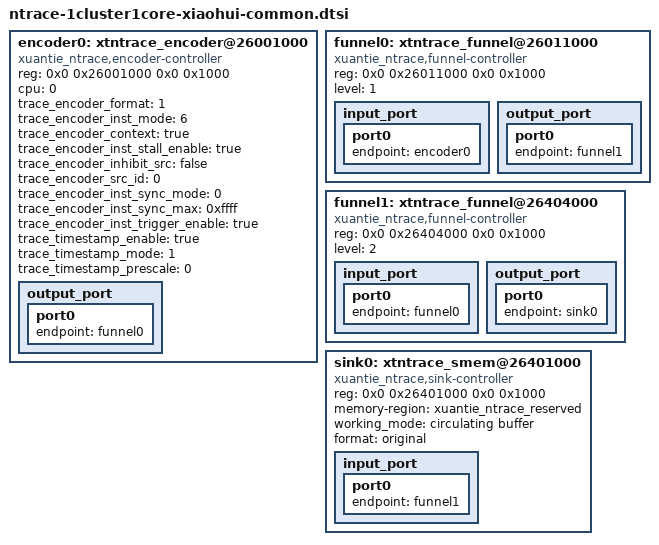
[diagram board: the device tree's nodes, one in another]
		encoder0: xtntrace_encoder@26001000 {
			compatible = "xuantie_ntrace,encoder-controller";
			reg = <0x0 0x26001000 0x0 0x1000>;
			// component special info
			cpu = <0>;
			trace_encoder_format = <1>;
			trace_encoder_inst_mode = <6>;
			trace_encoder_context = "true";
			trace_encoder_inst_stall_enable = "true";
			// src
			trace_encoder_inhibit_src = "false";
			trace_encoder_src_id = <0>;
			// sync mode
			trace_encoder_inst_sync_mode = <0>;
			trace_encoder_inst_sync_max = <0xffff>;
			// cpu trigger
			trace_encoder_inst_trigger_enable = "true";
			// timestamp
			trace_timestamp_enable = "true";
			trace_timestamp_mode = <1>;
			trace_timestamp_prescale = <0>;
			// connect component
			output_port {
				port0 {
					endpoint = <&funnel0>;
				};
			};
		};

		funnel0: xtntrace_funnel@26011000 {
			compatible = "xuantie_ntrace,funnel-controller";
			reg = <0x0 0x26011000 0x0 0x1000>;
			level = <1>;
			input_port {
				port0 {
					endpoint = <&encoder0>;
				};
			};
			output_port {
				port0 {
					endpoint = <&funnel1>;
				};
			};
		};
		funnel1: xtntrace_funnel@26404000 {
			compatible = "xuantie_ntrace,funnel-controller";
			reg = <0x0 0x26404000 0x0 0x1000>;
			level = <2>;
			input_port {
				port0 {
					endpoint = <&funnel0>;
				};
			};
			output_port {
				port0 {
					endpoint = <&sink0>;
				};
			};
		};

		sink0: xtntrace_smem@26401000 {
			compatible = "xuantie_ntrace,sink-controller";
			reg = <0x0 0x26401000 0x0 0x1000>;
			// component special info
			memory-region = <&xuantie_ntrace_reserved>;
			working_mode = "circulating buffer";
			format = "original";
			input_port {
				port0 {
					endpoint = <&funnel1>;
				};
			};
		};
